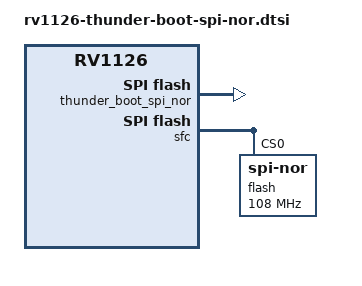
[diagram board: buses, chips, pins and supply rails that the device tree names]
// SPDX-License-Identifier: (GPL-2.0+ OR MIT)
/*
 * Copyright (c) 2020 Rockchip Electronics Co., Ltd.
 */

#include "rv1126-thunder-boot.dtsi"

/ {
	thunder_boot_spi_nor: thunder-boot-spi-nor {
		compatible = "rockchip,thunder-boot-sfc";
		reg = <0xffc90000 0x4000>;
		memory-region-src = <&ramdisk_c>;
		memory-region-dst = <&ramdisk_r>;
	};
};

&sfc {
	status = "okay";

	flash@0 {
		compatible = "jedec,spi-nor";
		reg = <0>;
		spi-max-frequency = <108000000>;
		spi-rx-bus-width = <2>;
		spi-tx-bus-width = <2>;
	};
};
